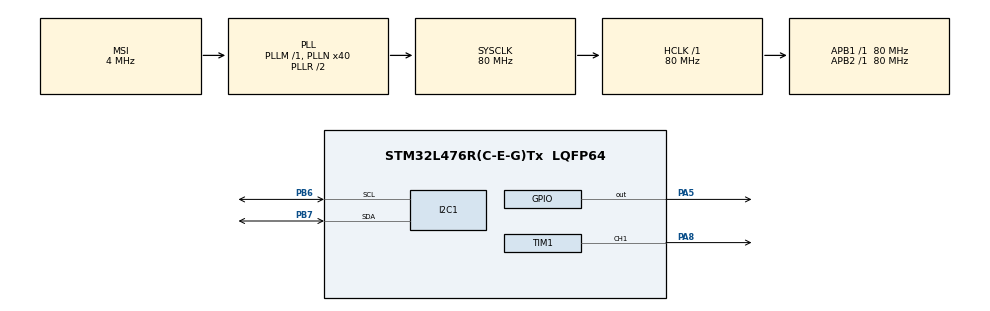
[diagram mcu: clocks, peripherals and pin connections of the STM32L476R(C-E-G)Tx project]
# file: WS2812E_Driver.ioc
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Dma.Request0=TIM1_CH1
Dma.TIM1_CH1.0.Direction=DMA_MEMORY_TO_PERIPH
Dma.TIM1_CH1.0.Instance=DMA1_Channel2
Dma.TIM1_CH1.0.MemDataAlignment=DMA_MDATAALIGN_HALFWORD
Dma.TIM1_CH1.0.MemInc=DMA_MINC_ENABLE
Dma.TIM1_CH1.0.Mode=DMA_NORMAL
Dma.TIM1_CH1.0.PeriphDataAlignment=DMA_PDATAALIGN_HALFWORD
Dma.TIM1_CH1.0.PeriphInc=DMA_PINC_DISABLE
Dma.TIM1_CH1.0.Priority=DMA_PRIORITY_HIGH
I2C1.Timing=0x10D19CE4
Mcu.Family=STM32L4
Mcu.Name=STM32L476R(C-E-G)Tx
Mcu.Package=LQFP64
NVIC.DMA1_Channel2_IRQn=true\:0\:0\:false\:false\:true\:false\:true\:true
NVIC.PriorityGroup=NVIC_PRIORITYGROUP_4
PA5.Signal=GPIO_Output
PA8.Signal=S_TIM1_CH1
PB6.Mode=I2C
PB6.Signal=I2C1_SCL
PB7.Mode=I2C
PB7.Signal=I2C1_SDA
ProjectManager.HeapSize=0x200
ProjectManager.StackSize=0x400
ProjectManager.TargetToolchain=STM32CubeIDE
RCC.AHBFreq_Value=80000000
RCC.APB1Freq_Value=80000000
RCC.APB1TimFreq_Value=80000000
RCC.APB2Freq_Value=80000000
RCC.APB2TimFreq_Value=80000000
RCC.CortexFreq_Value=80000000
RCC.HCLKFreq_Value=80000000
RCC.HSE_VALUE=8000000
RCC.HSI_VALUE=16000000
RCC.LSE_VALUE=32768
RCC.MSI_VALUE=4000000
RCC.PLLN=40
RCC.SYSCLKFreq_VALUE=80000000
RCC.SYSCLKSource=RCC_SYSCLKSOURCE_PLLCLK
RCC.VCOOutputFreq_Value=160000000
SH.S_TIM1_CH1.0=TIM1_CH1,PWM Generation1 CH1
TIM1.Channel-PWM\ Generation1\ CH1=TIM_CHANNEL_1
TIM1.Period=99
board=custom

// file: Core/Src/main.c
/* USER CODE BEGIN Header */
/**
  ******************************************************************************
  * @file           : main.c
  * @brief          : Main program body
  ******************************************************************************
  * @attention
  *
  * Copyright (c) 2026 STMicroelectronics.
  * All rights reserved.
  *
  * This software is licensed under terms that can be found in the LICENSE file
  * in the root directory of this software component.
  * If no LICENSE file comes with this software, it is provided AS-IS.
  *
  ******************************************************************************
  */
/* USER CODE END Header */
#include "main.h"
#include "dma.h"
#include "i2c.h"
#include "tim.h"
#include "gpio.h"
#include "lis3dh.h"
#include <math.h>
#include "lis3dh.h"
#include "accel_capture.h"
#include "lis3dh.h"
#include "impact_detection.h"
/* USER CODE END Includes */

void SystemClock_Config(void);

int main(void)
{

  /* MCU Configuration--------------------------------------------------------*/

  /* Reset of all peripherals, Initializes the Flash interface and the Systick. */
  HAL_Init();

  /* Configure the system clock */
  SystemClock_Config();

  /* Initialize all configured peripherals */
  MX_GPIO_Init();
  MX_DMA_Init();
  MX_TIM1_Init();
  MX_I2C1_Init();

  /* USER CODE BEGIN 2 */

  HAL_StatusTypeDef accel_status = LIS3DH_Init();

  uint8_t data_ready = 0;

  float accel_x = 0.0f;
  float accel_y = 0.0f;
  float accel_z = 0.0f;

  /* USER CODE END 2 */

  /* Infinite loop */
  while (1)
  {

	  if (accel_status == HAL_OK)
	  {
	      HAL_StatusTypeDef status =
	          LIS3DH_DataReady(&data_ready);

	      if (status == HAL_OK && data_ready)
	      {
	          status = LIS3DH_ReadAcceleration(
	              &accel_x,
	              &accel_y,
	              &accel_z
	          );

	          if (status == HAL_OK)
	          {
	              Impact_ProcessSample(
	                  accel_x,
	                  accel_y,
	                  accel_z
	              );
	          }
	      }
	  }

  }
}

void SystemClock_Config(void)
{
  RCC_OscInitTypeDef RCC_OscInitStruct = {0};
  RCC_ClkInitTypeDef RCC_ClkInitStruct = {0};

  /** Configure the main internal regulator output voltage
  */
  if (HAL_PWREx_ControlVoltageScaling(PWR_REGULATOR_VOLTAGE_SCALE1) != HAL_OK)
  {
    Error_Handler();
  }

  /** Initializes the RCC Oscillators according to the specified parameters
  * in the RCC_OscInitTypeDef structure.
  */
  RCC_OscInitStruct.OscillatorType = RCC_OSCILLATORTYPE_MSI;
  RCC_OscInitStruct.MSIState = RCC_MSI_ON;
  RCC_OscInitStruct.MSICalibrationValue = 0;
  RCC_OscInitStruct.MSIClockRange = RCC_MSIRANGE_6;
  RCC_OscInitStruct.PLL.PLLState = RCC_PLL_ON;
  RCC_OscInitStruct.PLL.PLLSource = RCC_PLLSOURCE_MSI;
  RCC_OscInitStruct.PLL.PLLM = 1;
  RCC_OscInitStruct.PLL.PLLN = 40;
  RCC_OscInitStruct.PLL.PLLP = RCC_PLLP_DIV7;
  RCC_OscInitStruct.PLL.PLLQ = RCC_PLLQ_DIV2;
  RCC_OscInitStruct.PLL.PLLR = RCC_PLLR_DIV2;
  if (HAL_RCC_OscConfig(&RCC_OscInitStruct) != HAL_OK)
  {
    Error_Handler();
  }

  /** Initializes the CPU, AHB and APB buses clocks
  */
  RCC_ClkInitStruct.ClockType = RCC_CLOCKTYPE_HCLK|RCC_CLOCKTYPE_SYSCLK
                              |RCC_CLOCKTYPE_PCLK1|RCC_CLOCKTYPE_PCLK2;
  RCC_ClkInitStruct.SYSCLKSource = RCC_SYSCLKSOURCE_PLLCLK;
  RCC_ClkInitStruct.AHBCLKDivider = RCC_SYSCLK_DIV1;
  RCC_ClkInitStruct.APB1CLKDivider = RCC_HCLK_DIV1;
  RCC_ClkInitStruct.APB2CLKDivider = RCC_HCLK_DIV1;

  if (HAL_RCC_ClockConfig(&RCC_ClkInitStruct, FLASH_LATENCY_4) != HAL_OK)
  {
    Error_Handler();
  }
}

void Error_Handler(void)
{
  __disable_irq();
  while (1)
  {
  }
}
